AUTOSAR XML (schema 4-0-3)
package /ComponentTypes
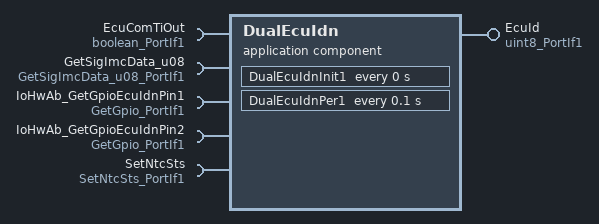
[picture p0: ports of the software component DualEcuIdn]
  application sw component type DualEcuIdn
    provide port EcuId: nonqueued-sender-com-spec{data-element=Val, init-value=0}, provided-interface=uint8_PortIf1
    5 x require port:
      EcuComTiOut: nonqueued-receiver-com-spec{data-element=Logl, filter=data-filter-type=ALWAYS, init-value=0}, required-interface=boolean_PortIf1
      GetSigImcData_u08: client-com-spec=Oper, required-interface=GetSigImcData_u08_PortIf1
      IoHwAb_GetGpioEcuIdnPin1: client-com-spec=Oper, required-interface=GetGpio_PortIf1
      IoHwAb_GetGpioEcuIdnPin2: client-com-spec=Oper, required-interface=GetGpio_PortIf1
      SetNtcSts: client-com-spec=Oper, required-interface=SetNtcSts_PortIf1
    behavior DualEcuIdn_InternalBehavior
      ar-typed-per-instance-memorys:
        data EcuIdInt: sw-calibration-access=READ-ONLY, type=uint8
        data EcuIdnEvlnCmpl: sw-calibration-access=READ-ONLY, type=boolean
        data SecdryEcuIdnReqTiOutCntr: sw-calibration-access=READ-ONLY, type=uint8
      timing event DualEcuIdn_InitEvent: start-on-event=DualEcuIdnInit1, period=0
      timing event TMT_DualEcuIdnPer1: start-on-event=DualEcuIdnPer1, period=0.1
      runnable DualEcuIdnInit1
        data-send-points:
          access SEND_EcuId_Val: accessed-variable=EcuId.Val
        sync call SC_IoHwAb_GetGpioEcuIdnPin1_Oper: operation=IoHwAb_GetGpioEcuIdnPin1.Oper, timeout=0
        sync call SC_IoHwAb_GetGpioEcuIdnPin2_Oper: operation=IoHwAb_GetGpioEcuIdnPin2.Oper, timeout=0
      runnable DualEcuIdnPer1
        data-receive-point-by-arguments:
          access REC_EcuComTiOut_Logl: accessed-variable=EcuComTiOut.Logl
        sync call SC_GetSigImcData_u08_Oper: operation=GetSigImcData_u08.Oper, timeout=0
        sync call SC_SetNtcSts_Oper: operation=SetNtcSts.Oper, timeout=0
  swc implementation DualEcuIdn_Implementation: behavior=DualEcuIdn_InternalBehavior
    code-descriptors:
      code Default: artifact-descriptors=autosar-engineering-object={short-label=Default, category=SWSRC}
